# AC33Mx064 register map
Vendor: ABOV Semiconductor Co., Ltd.; File version: 0.1
ARM 32-bit Cortex-M3 Microcontroller based device.
CPU: CM3 r1p0, little endian, no MPU, no FPU, 3 interrupt priority bits
Registers are 32-bit, read-write, reset 0x0 unless marked. A register's access mark holds for its fields unless they carry their own. Offsets are from the block's base; lines under a group give offsets from that group; [hi:lo] are bit positions; {n}, {i} and the like mark numbered series; 'fields as' and 'values as' point back to an identical list; <NAME> marks a mode.

## Memory map
0x40000000 SCU size 0x100 — SYSTEM CONTROL UNIT
0x40000100 FM size 0x100 — FLASH MEMORY CONTROLLER
0x40000200 WDT size 0x100 — WATCH-DOG TIMER
0x40000400 DC0 size 0x10 — DIRECT MEMORY ACCESS CONTROLLER
0x40000410 DC1 size 0x10
0x40000420 DC2 size 0x10
0x40000430 DC3 size 0x10
0x40001000 PCA size 0x100 — PORT CONTROL UNIT
0x40001100 PCB size 0x100
0x40001200 PCC size 0x100
0x40001300 PCD size 0x100
0x40001FF0 PORTEN size 0x10 — Port Access Eable
0x40002000 PA size 0x100 — GENERAL PURPOSE I/O
0x40002100 PB size 0x100
0x40002200 PC size 0x100
0x40002300 PD size 0x100
0x40003000 T0 size 0x20 — 16-BIT TIMER
0x40003020 T1 size 0x20
0x40003040 T2 size 0x20
0x40003060 T3 size 0x20
0x40003100 T8 size 0x20
0x40003120 T9 size 0x20
0x40003140 TGECR size 0x10 — Timer Group Encoder Control Register
0x40004000 MP0 size 0x1000 — MOTOR PULSE-WIDTH-MODULATOR
0x40008000 U0 size 0x100 — UNIVERSAL ASYNCHRONOUS RECEIVER/TRANSMITTER
0x40008100 U1 size 0x100
0x40009000 SP0 size 0x100 — SERIAL PERIPHERAL INTERFACE
0x4000A000 IC0 size 0x100 — IIC Interface
0x4000B000 AD0 size 0x100 — 12-BIT A/D CONVERTER
0x4000B100 AD1 size 0x100

## Interrupts
0 LVDDETECT (SCU)
1 SCLKFAIL (SCU)
2 XOSCFAIL (SCU)
3 WDT
5 TIMER0 (T0)
6 TIMER1 (T1)
7 TIMER2 (T2)
8 TIMER3 (T3)
13 TIMER8 (T8)
14 TIMER9 (T9)
16 GPIOAE (PCA)
17 GPIOAO (PCA)
18 GPIOBE (PCB)
19 GPIOBO (PCB)
20 GPIOCE (PCC)
21 GPIOCO (PCC)
22 GPIODE (PCD)
23 GPIODO (PCD)
24 MPWM0 (MP0)
25 MPWM0PROT (MP0)
26 MPWM0OVV (MP0)
32 SPI0 (SP0)
36 IIC0 (IC0)
38 UART0 (U0)
39 UART1 (U1)
43 ADC0 (AD0)
44 ADC1 (AD1)

## PCA — PORT CONTROL UNIT
Base 0x40001000
Same registers: PCB 0x40001100, PCC 0x40001200, PCD 0x40001300
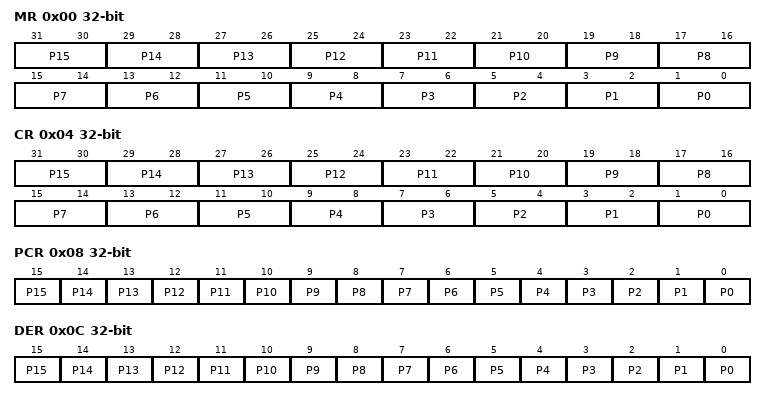
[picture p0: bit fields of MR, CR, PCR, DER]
0x00 MR — PORT n Pin MUX Register
  [31:30] P15 — P15 Pin Mux select
  [29:28] P14 — P14 MUX SEL
  [27:26] P13 — P13 Pin Mux select
  [25:24] P12 — P12 MUX SEL
  [23:22] P11 — P11 Pin Mux select
  [21:20] P10 — P10 MUX SEL
  [19:18] P9 — P9 Pin Mux select
  [17:16] P8 — P8 MUX SEL
  [15:14] P7 — P7 Pin Mux select
  [13:12] P6 — P6 MUX SEL
  [11:10] P5 — P5 Pin Mux select
  [9:8] P4 — P4 MUX SEL
  [7:6] P3 — P3 Pin Mux select
  [5:4] P2 — P2 MUX SEL
  [3:2] P1 — P1 Pin Mux select
  [1:0] P0 — P0 MUX SEL
0x04 CR — PORT n Pin Control Register
  [31:30] P15 — P15 control select
  [29:28] P14 — P14 control SEL
  [27:26] P13 — P13 control select
  [25:24] P12 — P12 control SEL
  [23:22] P11 — P11 control select
  [21:20] P10 — P10 control SEL
  [19:18] P9 — P9 control select
  [17:16] P8 — P8 control SEL
  [15:14] P7 — P7 control select
  [13:12] P6 — P6 control SEL
  [11:10] P5 — P5 control select
  [9:8] P4 — P4 control SEL
  [7:6] P3 — P3 control select
  [5:4] P2 — P2 control SEL
  [3:2] P1 — P1 control select
  [1:0] P0 — P0 control SEL
0x08 PCR — PORT n Pull-up Resistor Control Register
  [n] P{n} (n=0..15) — P{n} pull-up enable
0x0C DER — PORT n Debounce Enable Register
  [n] P{n} (n=0..15) — P{n} Debounce enable
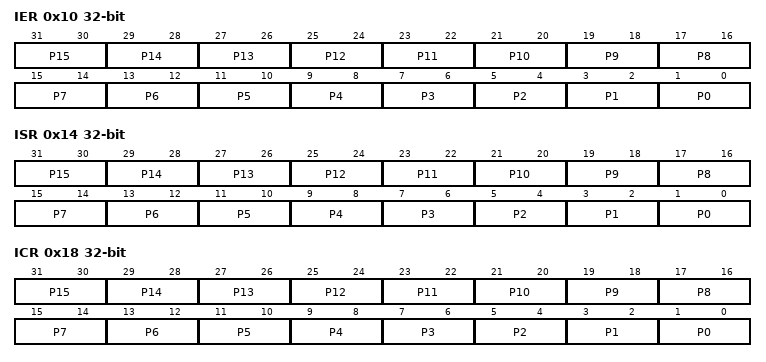
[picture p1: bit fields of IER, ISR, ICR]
0x10 IER — PORT n Interrupt Enable Register
  [31:30] P15 — P15 interrupt select
  [29:28] P14 — P14 interrupt SEL
  [27:26] P13 — P13 interrupt select
  [25:24] P12 — P12 interrupt SEL
  [23:22] P11 — P11 interrupt select
  [21:20] P10 — P10 interrupt SEL
  [19:18] P9 — P9 interrupt select
  [17:16] P8 — P8 interrupt SEL
  [15:14] P7 — P7 interrupt select
  [13:12] P6 — P6 interrupt SEL
  [11:10] P5 — P5 interrupt select
  [9:8] P4 — P4 interrupt SEL
  [7:6] P3 — P3 interrupt select
  [5:4] P2 — P2 interrupt SEL
  [3:2] P1 — P1 interrupt select
  [1:0] P0 — P0 interrupt enable
0x14 ISR — PORT n Interrupt Status Register
  [2n+1:2n] P{n} (n=0..15) — P{n} interrupt status
0x18 ICR — PORT n Interrupt Control Register
  [2n+1:2n] P{n} (n=0..15) — P{n} interrupt control

## Licence text in the file
THIS SOFTWARE IS PROVIDED "AS IS". NO WARRANTIES, WHETHER EXPRESS, IMPLIED. OR STATUTORY, INCLUDING, BUT NOT LIMITED TO, IMPLIED WARRANTIES OF. MERCHANTABILITY AND FITNESS FOR A PARTICULAR PURPOSE APPLY TO THIS SOFTWARE. ARM SHALL NOT, IN ANY CIRCUMSTANCES, BE LIABLE FOR SPECIAL, INCIDENTAL, OR. CONSEQUENTIAL DAMAGES, FOR ANY REASON WHATSOEVER.
